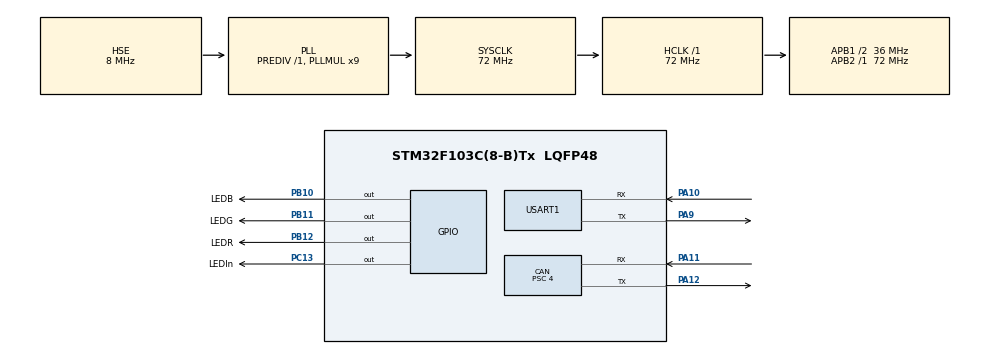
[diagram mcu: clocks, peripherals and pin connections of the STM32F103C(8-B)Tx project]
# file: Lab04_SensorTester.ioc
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CAN.BS1=CAN_BS1_13TQ
CAN.BS2=CAN_BS2_4TQ
CAN.CalculateBaudRate=500000
CAN.CalculateTimeBit=2000
CAN.CalculateTimeQuantum=111.11111111111111
CAN.Prescaler=4
CAN.SJW=CAN_SJW_2TQ
Mcu.Family=STM32F1
Mcu.Name=STM32F103C(8-B)Tx
Mcu.Package=LQFP48
NVIC.CAN1_RX1_IRQn=true\:0\:0\:false\:false\:true\:true\:true\:true
NVIC.CAN1_SCE_IRQn=true\:0\:0\:false\:false\:true\:true\:true\:true
NVIC.PriorityGroup=NVIC_PRIORITYGROUP_4
NVIC.USB_HP_CAN1_TX_IRQn=true\:0\:0\:false\:false\:true\:true\:true\:true
NVIC.USB_LP_CAN1_RX0_IRQn=true\:0\:0\:false\:false\:true\:true\:true\:true
PA10.Mode=Asynchronous
PA10.Signal=USART1_RX
PA11.Mode=CAN_Activate
PA11.Signal=CAN_RX
PA12.Mode=CAN_Activate
PA12.Signal=CAN_TX
PA13.Mode=Serial_Wire
PA13.Signal=SYS_JTMS-SWDIO
PA14.Mode=Serial_Wire
PA14.Signal=SYS_JTCK-SWCLK
PA9.Mode=Asynchronous
PA9.Signal=USART1_TX
PB10.GPIO_Label=LEDB
PB10.Signal=GPIO_Output
PB11.GPIO_Label=LEDG
PB11.Signal=GPIO_Output
PB12.GPIO_Label=LEDR
PB12.Signal=GPIO_Output
PC13-TAMPER-RTC.GPIO_Label=LEDIn
PC13-TAMPER-RTC.Signal=GPIO_Output
PD0-OSC_IN.Mode=HSE-External-Oscillator
PD0-OSC_IN.Signal=RCC_OSC_IN
PD1-OSC_OUT.Mode=HSE-External-Oscillator
PD1-OSC_OUT.Signal=RCC_OSC_OUT
ProjectManager.HeapSize=0x200
ProjectManager.StackSize=0x400
ProjectManager.TargetToolchain=STM32CubeIDE
RCC.AHBFreq_Value=72000000
RCC.APB1CLKDivider=RCC_HCLK_DIV2
RCC.APB1Freq_Value=36000000
RCC.APB1TimFreq_Value=72000000
RCC.APB2Freq_Value=72000000
RCC.APB2TimFreq_Value=72000000
RCC.HCLKFreq_Value=72000000
RCC.PLLMUL=RCC_PLL_MUL9
RCC.PLLSourceVirtual=RCC_PLLSOURCE_HSE
RCC.SYSCLKFreq_VALUE=72000000
RCC.SYSCLKSource=RCC_SYSCLKSOURCE_PLLCLK
RCC.USBFreq_Value=72000000
USART1.VirtualMode=VM_ASYNC
board=custom

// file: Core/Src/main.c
/* USER CODE BEGIN Header */
/**
 ******************************************************************************
 * @file           : main.c
 * @brief          : Main program body
 ******************************************************************************
 * @attention
 *
 * Copyright (c) 2023 STMicroelectronics.
 * All rights reserved.
 *
 * This software is licensed under terms that can be found in the LICENSE file
 * in the root directory of this software component.
 * If no LICENSE file comes with this software, it is provided AS-IS.
 *
 ******************************************************************************
 */
/* USER CODE END Header */
#include "main.h"

/* USER CODE BEGIN Includes */
#include "DiagnosticDefine.h"
/* USER CODE END Includes */

CAN_HandleTypeDef hcan;

UART_HandleTypeDef huart1;

void SystemClock_Config(void);
static void MX_GPIO_Init(void);
static void MX_CAN_Init(void);
static void MX_USART1_UART_Init(void);

int main(void)
{

  /* MCU Configuration--------------------------------------------------------*/

  /* Reset of all peripherals, Initializes the Flash interface and the Systick. */
  HAL_Init();

  /* Configure the system clock */
  SystemClock_Config();

  /* Initialize all configured peripherals */
  MX_GPIO_Init();
  MX_CAN_Init();
  MX_USART1_UART_Init();
  /* USER CODE BEGIN 2 */
	DiagnosticService_Init();
	uint8_t WData[2] = { 0x12, 0x13 };
  /* USER CODE END 2 */

  /* Infinite loop */
  /* USER CODE BEGIN WHILE */
	while (1) {
		HAL_GPIO_WritePin(LEDB_GPIO_Port, LEDB_Pin, 0);
		HAL_GPIO_WritePin(LEDG_GPIO_Port, LEDG_Pin, 0);
		HAL_GPIO_WritePin(LEDR_GPIO_Port, LEDR_Pin, 0);
		HAL_Delay(1000);
		Tester_SecurityAccess_RequestService();
		HAL_Delay(2000);
    /* USER CODE END WHILE */

	}
}

void SystemClock_Config(void)
{
  RCC_OscInitTypeDef RCC_OscInitStruct = {0};
  RCC_ClkInitTypeDef RCC_ClkInitStruct = {0};

  /** Initializes the RCC Oscillators according to the specified parameters
  * in the RCC_OscInitTypeDef structure.
  */
  RCC_OscInitStruct.OscillatorType = RCC_OSCILLATORTYPE_HSE;
  RCC_OscInitStruct.HSEState = RCC_HSE_ON;
  RCC_OscInitStruct.HSEPredivValue = RCC_HSE_PREDIV_DIV1;
  RCC_OscInitStruct.HSIState = RCC_HSI_ON;
  RCC_OscInitStruct.PLL.PLLState = RCC_PLL_ON;
  RCC_OscInitStruct.PLL.PLLSource = RCC_PLLSOURCE_HSE;
  RCC_OscInitStruct.PLL.PLLMUL = RCC_PLL_MUL9;
  if (HAL_RCC_OscConfig(&RCC_OscInitStruct) != HAL_OK)
  {
    Error_Handler();
  }

  /** Initializes the CPU, AHB and APB buses clocks
  */
  RCC_ClkInitStruct.ClockType = RCC_CLOCKTYPE_HCLK|RCC_CLOCKTYPE_SYSCLK
                              |RCC_CLOCKTYPE_PCLK1|RCC_CLOCKTYPE_PCLK2;
  RCC_ClkInitStruct.SYSCLKSource = RCC_SYSCLKSOURCE_PLLCLK;
  RCC_ClkInitStruct.AHBCLKDivider = RCC_SYSCLK_DIV1;
  RCC_ClkInitStruct.APB1CLKDivider = RCC_HCLK_DIV2;
  RCC_ClkInitStruct.APB2CLKDivider = RCC_HCLK_DIV1;

  if (HAL_RCC_ClockConfig(&RCC_ClkInitStruct, FLASH_LATENCY_2) != HAL_OK)
  {
    Error_Handler();
  }
}

static void MX_CAN_Init(void)
{

  hcan.Instance = CAN1;
  hcan.Init.Prescaler = 4;
  hcan.Init.Mode = CAN_MODE_NORMAL;
  hcan.Init.SyncJumpWidth = CAN_SJW_2TQ;
  hcan.Init.TimeSeg1 = CAN_BS1_13TQ;
  hcan.Init.TimeSeg2 = CAN_BS2_4TQ;
  hcan.Init.TimeTriggeredMode = DISABLE;
  hcan.Init.AutoBusOff = DISABLE;
  hcan.Init.AutoWakeUp = DISABLE;
  hcan.Init.AutoRetransmission = DISABLE;
  hcan.Init.ReceiveFifoLocked = DISABLE;
  hcan.Init.TransmitFifoPriority = DISABLE;
  if (HAL_CAN_Init(&hcan) != HAL_OK)
  {
    Error_Handler();
  }

}

static void MX_USART1_UART_Init(void)
{

  huart1.Instance = USART1;
  huart1.Init.BaudRate = 115200;
  huart1.Init.WordLength = UART_WORDLENGTH_8B;
  huart1.Init.StopBits = UART_STOPBITS_1;
  huart1.Init.Parity = UART_PARITY_NONE;
  huart1.Init.Mode = UART_MODE_TX_RX;
  huart1.Init.HwFlowCtl = UART_HWCONTROL_NONE;
  huart1.Init.OverSampling = UART_OVERSAMPLING_16;
  if (HAL_UART_Init(&huart1) != HAL_OK)
  {
    Error_Handler();
  }

}

static void MX_GPIO_Init(void)
{
  GPIO_InitTypeDef GPIO_InitStruct = {0};

  /* GPIO Ports Clock Enable */
  __HAL_RCC_GPIOC_CLK_ENABLE();
  __HAL_RCC_GPIOD_CLK_ENABLE();
  __HAL_RCC_GPIOB_CLK_ENABLE();
  __HAL_RCC_GPIOA_CLK_ENABLE();

  /*Configure GPIO pin Output Level */
  HAL_GPIO_WritePin(LEDIn_GPIO_Port, LEDIn_Pin, GPIO_PIN_RESET);

  /*Configure GPIO pin Output Level */
  HAL_GPIO_WritePin(GPIOB, LEDB_Pin|LEDG_Pin|LEDR_Pin, GPIO_PIN_RESET);

  /*Configure GPIO pin : LEDIn_Pin */
  GPIO_InitStruct.Pin = LEDIn_Pin;
  GPIO_InitStruct.Mode = GPIO_MODE_OUTPUT_PP;
  GPIO_InitStruct.Pull = GPIO_NOPULL;
  GPIO_InitStruct.Speed = GPIO_SPEED_FREQ_LOW;
  HAL_GPIO_Init(LEDIn_GPIO_Port, &GPIO_InitStruct);

  /*Configure GPIO pins : LEDB_Pin LEDG_Pin LEDR_Pin */
  GPIO_InitStruct.Pin = LEDB_Pin|LEDG_Pin|LEDR_Pin;
  GPIO_InitStruct.Mode = GPIO_MODE_OUTPUT_PP;
  GPIO_InitStruct.Pull = GPIO_NOPULL;
  GPIO_InitStruct.Speed = GPIO_SPEED_FREQ_LOW;
  HAL_GPIO_Init(GPIOB, &GPIO_InitStruct);

}

/* USER CODE BEGIN 4 */
void HAL_CAN_RxFifo0MsgPendingCallback(CAN_HandleTypeDef *hcan) {
	HAL_GPIO_WritePin(LEDB_GPIO_Port, LEDB_Pin, 1);
	CanTP_RcvCallback();
}
/* USER CODE END 4 */

void Error_Handler(void)
{
	__disable_irq();
	while (1) {
	}
}
